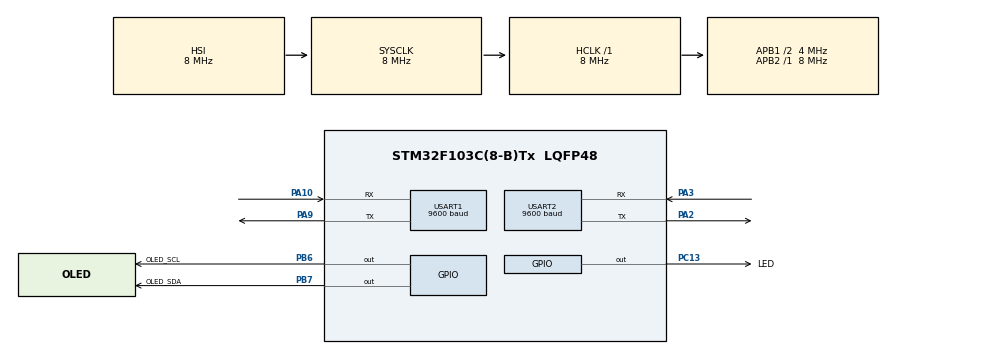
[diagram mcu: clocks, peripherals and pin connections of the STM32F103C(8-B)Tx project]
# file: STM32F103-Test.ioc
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Mcu.Family=STM32F1
Mcu.Name=STM32F103C(8-B)Tx
Mcu.Package=LQFP48
NVIC.PriorityGroup=NVIC_PRIORITYGROUP_4
NVIC.USART2_IRQn=true\:0\:0\:false\:false\:true\:true\:true\:true
PA10.Mode=Asynchronous
PA10.Signal=USART1_RX
PA13.Mode=Serial_Wire
PA13.Signal=SYS_JTMS-SWDIO
PA14.Mode=Serial_Wire
PA14.Signal=SYS_JTCK-SWCLK
PA2.Mode=Asynchronous
PA2.Signal=USART2_TX
PA3.Mode=Asynchronous
PA3.Signal=USART2_RX
PA9.Mode=Asynchronous
PA9.Signal=USART1_TX
PB6.GPIO_Label=OLED_SCL
PB6.GPIO_PuPd=GPIO_PULLUP
PB6.PinState=GPIO_PIN_SET
PB6.Signal=GPIO_Output
PB7.GPIO_Label=OLED_SDA
PB7.GPIO_PuPd=GPIO_PULLUP
PB7.PinState=GPIO_PIN_SET
PB7.Signal=GPIO_Output
PC13-TAMPER-RTC.GPIO_Label=LED
PC13-TAMPER-RTC.Signal=GPIO_Output
ProjectManager.HeapSize=0x200
ProjectManager.StackSize=0x400
ProjectManager.TargetToolchain=MDK-ARM V5.32
RCC.AHBFreq_Value=8000000
RCC.APB1CLKDivider=RCC_HCLK_DIV2
RCC.APB1Freq_Value=4000000
RCC.APB1TimFreq_Value=8000000
RCC.APB2Freq_Value=8000000
RCC.APB2TimFreq_Value=8000000
RCC.HCLKFreq_Value=8000000
RCC.PLLMUL=RCC_PLL_MUL16
RCC.SYSCLKFreq_VALUE=8000000
RCC.USBFreq_Value=64000000
USART1.BaudRate=9600
USART1.VirtualMode=VM_ASYNC
USART2.BaudRate=9600
USART2.VirtualMode=VM_ASYNC
board=custom

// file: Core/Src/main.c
/* USER CODE BEGIN Header */
/**
  ******************************************************************************
  * @file           : main.c
  * @brief          : Main program body
  ******************************************************************************
  * @attention
  *
  * Copyright (c) 2023 STMicroelectronics.
  * All rights reserved.

本程序实现超声波测距串口1输出和OLED显示距离功能（使用十六进制模式，关于十六进制模式，可以参考说明手册）
单片机型号：STM32F103C8T6，使用内部晶振，总线频率8MHZ，串口1和串口2的波特率都为9600
-----------------------------------------------------------------
硬件接口：
测试板-------------0.96寸OLED-IIC接口(GND VCC SCL SDA)
PB6-----------------------SCL
PB7-----------------------SDA
---------------------------------
测试板-------------超声波接收模块（5V-可接3.3-5V电源，GND接地）
PA3(RX2)---------------TXD
PA2(TX2)---------------不接
-----------------------------------------------------------------
功能说明：
1、用户购买本店测试底板
用TYPE-C数据线把电脑和底板连接，电脑端打开串口助手，即可看到距离信息（距离计算请参考说明手册）
2、用户没有购买本店测试底板
串口1的PA9(TX1)引脚接到USB转串口模块的RXD口上，即可以通过串口看到距离信息
-----------------------------------------------------------------
只要液晶屏接口按照上述OLED接法，即可在液晶屏显示距离信息和相关测距信息，具体信息如下：
如果没有有效数据：显示
Data invalid
----------
------------------------------
如果数据错误：显示
Data invalid
Data Error
------------------------------
如果探测距离太近：显示
Data invalid
Too close
------------------------------
如果数据有效：显示
Now Distance
实时距离：XXXmm
-----------------------------------------------------------------

******************************************************************************
  */
/* USER CODE END Header */
#include "main.h"
#include "usart.h"
#include "gpio.h"

/* USER CODE BEGIN Includes */
#include "MyApplication.h"
/* USER CODE END Includes */

void SystemClock_Config(void);

int main(void)
{

  /* MCU Configuration--------------------------------------------------------*/

  /* Reset of all peripherals, Initializes the Flash interface and the Systick. */
  HAL_Init();

  /* Configure the system clock */
  SystemClock_Config();

  /* Initialize all configured peripherals */
  MX_GPIO_Init();
  MX_USART2_UART_Init();
  MX_USART1_UART_Init();
  /* USER CODE BEGIN 2 */
	//初始化
  MyInit.Peripheral_Set();
  /* USER CODE END 2 */

  /* Infinite loop */
  /* USER CODE BEGIN WHILE */
  while (1)
  {
		//程序运行
		System.Run();

    /* USER CODE END WHILE */

  }
}

void SystemClock_Config(void)
{
  RCC_OscInitTypeDef RCC_OscInitStruct = {0};
  RCC_ClkInitTypeDef RCC_ClkInitStruct = {0};

  /** Initializes the RCC Oscillators according to the specified parameters
  * in the RCC_OscInitTypeDef structure.
  */
  RCC_OscInitStruct.OscillatorType = RCC_OSCILLATORTYPE_HSI;
  RCC_OscInitStruct.HSIState = RCC_HSI_ON;
  RCC_OscInitStruct.HSICalibrationValue = RCC_HSICALIBRATION_DEFAULT;
  RCC_OscInitStruct.PLL.PLLState = RCC_PLL_NONE;
  if (HAL_RCC_OscConfig(&RCC_OscInitStruct) != HAL_OK)
  {
    Error_Handler();
  }

  /** Initializes the CPU, AHB and APB buses clocks
  */
  RCC_ClkInitStruct.ClockType = RCC_CLOCKTYPE_HCLK|RCC_CLOCKTYPE_SYSCLK
                              |RCC_CLOCKTYPE_PCLK1|RCC_CLOCKTYPE_PCLK2;
  RCC_ClkInitStruct.SYSCLKSource = RCC_SYSCLKSOURCE_HSI;
  RCC_ClkInitStruct.AHBCLKDivider = RCC_SYSCLK_DIV1;
  RCC_ClkInitStruct.APB1CLKDivider = RCC_HCLK_DIV2;
  RCC_ClkInitStruct.APB2CLKDivider = RCC_HCLK_DIV1;

  if (HAL_RCC_ClockConfig(&RCC_ClkInitStruct, FLASH_LATENCY_0) != HAL_OK)
  {
    Error_Handler();
  }
}

void Error_Handler(void)
{
  __disable_irq();
  while (1)
  {
  }
}
